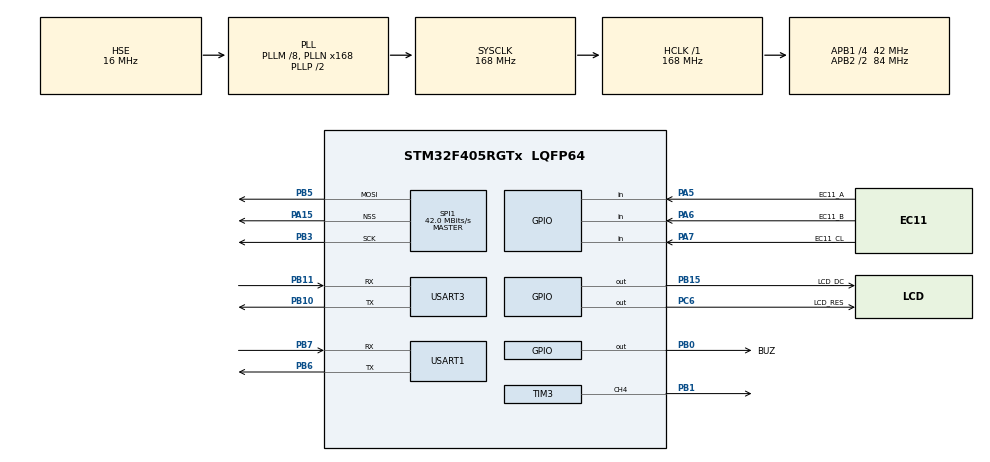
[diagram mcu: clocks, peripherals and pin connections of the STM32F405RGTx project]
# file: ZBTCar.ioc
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Dma.Request0=SPI1_TX
Dma.Request1=USART1_TX
Dma.Request2=USART3_TX
Dma.SPI1_TX.0.Direction=DMA_MEMORY_TO_PERIPH
Dma.SPI1_TX.0.FIFOMode=DMA_FIFOMODE_DISABLE
Dma.SPI1_TX.0.Instance=DMA2_Stream3
Dma.SPI1_TX.0.MemDataAlignment=DMA_MDATAALIGN_BYTE
Dma.SPI1_TX.0.MemInc=DMA_MINC_ENABLE
Dma.SPI1_TX.0.Mode=DMA_NORMAL
Dma.SPI1_TX.0.PeriphDataAlignment=DMA_PDATAALIGN_BYTE
Dma.SPI1_TX.0.PeriphInc=DMA_PINC_DISABLE
Dma.SPI1_TX.0.Priority=DMA_PRIORITY_LOW
Dma.USART1_TX.1.Direction=DMA_MEMORY_TO_PERIPH
Dma.USART1_TX.1.FIFOMode=DMA_FIFOMODE_DISABLE
Dma.USART1_TX.1.Instance=DMA2_Stream7
Dma.USART1_TX.1.MemDataAlignment=DMA_MDATAALIGN_BYTE
Dma.USART1_TX.1.MemInc=DMA_MINC_ENABLE
Dma.USART1_TX.1.Mode=DMA_NORMAL
Dma.USART1_TX.1.PeriphDataAlignment=DMA_PDATAALIGN_BYTE
Dma.USART1_TX.1.PeriphInc=DMA_PINC_DISABLE
Dma.USART1_TX.1.Priority=DMA_PRIORITY_LOW
Dma.USART3_TX.2.Direction=DMA_MEMORY_TO_PERIPH
Dma.USART3_TX.2.FIFOMode=DMA_FIFOMODE_DISABLE
Dma.USART3_TX.2.Instance=DMA1_Stream3
Dma.USART3_TX.2.MemDataAlignment=DMA_MDATAALIGN_BYTE
Dma.USART3_TX.2.MemInc=DMA_MINC_ENABLE
Dma.USART3_TX.2.Mode=DMA_NORMAL
Dma.USART3_TX.2.PeriphDataAlignment=DMA_PDATAALIGN_BYTE
Dma.USART3_TX.2.PeriphInc=DMA_PINC_DISABLE
Dma.USART3_TX.2.Priority=DMA_PRIORITY_LOW
FREERTOS.Tasks01=defaultTask,24,128,StartDefaultTask,Default,NULL,Dynamic,NULL,NULL
Mcu.Family=STM32F4
Mcu.Name=STM32F405RGTx
Mcu.Package=LQFP64
Mcu.UserConstants=LCD_SPI,hspi1;PWM_TIM,htim3;PWM_CH,TIM_CHANNEL_4;PC_UART,huart1;VESC_UART,huart3
NVIC.DMA1_Stream3_IRQn=true\:5\:0\:false\:false\:true\:true\:false\:true
NVIC.DMA2_Stream3_IRQn=true\:5\:0\:false\:false\:true\:true\:false\:true
NVIC.DMA2_Stream7_IRQn=true\:5\:0\:false\:false\:true\:true\:false\:true
NVIC.PriorityGroup=NVIC_PRIORITYGROUP_4
NVIC.TIM8_TRG_COM_TIM14_IRQn=true\:0\:0\:false\:false\:true\:false\:false\:true
NVIC.TimeBase=TIM8_TRG_COM_TIM14_IRQn
NVIC.TimeBaseIP=TIM14
NVIC.USART1_IRQn=true\:5\:0\:false\:false\:true\:true\:true\:true
NVIC.USART3_IRQn=true\:5\:0\:false\:false\:true\:true\:true\:true
PA13.Mode=Serial_Wire
PA13.Signal=SYS_JTMS-SWDIO
PA14.Mode=Serial_Wire
PA14.Signal=SYS_JTCK-SWCLK
PA15.Mode=NSS_Signal_Hard_Output
PA15.Signal=SPI1_NSS
PA5.GPIO_Label=EC11_A
PA5.Signal=GPIO_Input
PA6.GPIO_Label=EC11_B
PA6.Signal=GPIO_Input
PA7.GPIO_Label=EC11_CL
PA7.Signal=GPIO_Input
PB0.GPIO_Label=BUZ
PB0.Signal=GPIO_Output
PB1.Signal=S_TIM3_CH4
PB10.Mode=Asynchronous
PB10.Signal=USART3_TX
PB11.Mode=Asynchronous
PB11.Signal=USART3_RX
PB15.GPIO_Label=LCD_DC
PB15.GPIO_Speed=GPIO_SPEED_FREQ_VERY_HIGH
PB15.PinState=GPIO_PIN_SET
PB15.Signal=GPIO_Output
PB3.Mode=TX_Only_Simplex_Unidirect_Master
PB3.Signal=SPI1_SCK
PB5.Mode=TX_Only_Simplex_Unidirect_Master
PB5.Signal=SPI1_MOSI
PB6.Mode=Asynchronous
PB6.Signal=USART1_TX
PB7.Mode=Asynchronous
PB7.Signal=USART1_RX
PC6.GPIO_Label=LCD_RES
PC6.GPIO_Speed=GPIO_SPEED_FREQ_VERY_HIGH
PC6.PinState=GPIO_PIN_SET
PC6.Signal=GPIO_Output
PH0-OSC_IN.Mode=HSE-External-Oscillator
PH0-OSC_IN.Signal=RCC_OSC_IN
PH1-OSC_OUT.Mode=HSE-External-Oscillator
PH1-OSC_OUT.Signal=RCC_OSC_OUT
ProjectManager.HeapSize=0x800
ProjectManager.StackSize=0x800
ProjectManager.TargetToolchain=EWARM V8.32
RCC.48MHZClocksFreq_Value=84000000
RCC.AHBFreq_Value=168000000
RCC.APB1CLKDivider=RCC_HCLK_DIV4
RCC.APB1Freq_Value=42000000
RCC.APB1TimFreq_Value=84000000
RCC.APB2CLKDivider=RCC_HCLK_DIV2
RCC.APB2Freq_Value=84000000
RCC.APB2TimFreq_Value=168000000
RCC.CortexFreq_Value=168000000
RCC.HCLKFreq_Value=168000000
RCC.HSE_VALUE=16000000
RCC.HSI_VALUE=16000000
RCC.LSE_VALUE=32768
RCC.PLLM=8
RCC.PLLN=168
RCC.PLLSourceVirtual=RCC_PLLSOURCE_HSE
RCC.SYSCLKFreq_VALUE=168000000
RCC.SYSCLKSource=RCC_SYSCLKSOURCE_PLLCLK
RCC.VCOOutputFreq_Value=336000000
SH.S_TIM3_CH4.0=TIM3_CH4,PWM Generation4 CH4
SPI1.CalculateBaudRate=42.0 MBits/s
SPI1.Direction=SPI_DIRECTION_2LINES
SPI1.Mode=SPI_MODE_MASTER
SPI1.VirtualNSS=VM_NSSHARD
SPI1.VirtualType=VM_MASTER
TIM3.Channel-PWM\ Generation4\ CH4=TIM_CHANNEL_4
TIM3.Period=9999
TIM3.Prescaler=167
USART1.VirtualMode=VM_ASYNC
USART3.VirtualMode=VM_ASYNC
VP_FREERTOS_VS_CMSIS_V2.Mode=CMSIS_V2
VP_SYS_VS_tim14.Mode=TIM14
board=custom

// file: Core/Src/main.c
/* USER CODE BEGIN Header */
/**
  ******************************************************************************
  * @file           : main.c
  * @brief          : Main program body
  ******************************************************************************
  * @attention
  *
  * <h2><center>&copy; Copyright (c) 2021 STMicroelectronics.
  * All rights reserved.</center></h2>
  *
  * This software component is licensed by ST under Ultimate Liberty license
  * SLA0044, the "License"; You may not use this file except in compliance with
  * the License. You may obtain a copy of the License at:
  *                             www.st.com/SLA0044
  *
  ******************************************************************************
  */
/* USER CODE END Header */
#include "main.h"
#include "cmsis_os.h"
#include "dma.h"
#include "spi.h"
#include "tim.h"
#include "usart.h"
#include "gpio.h"

/* USER CODE BEGIN Includes */
#include "lcd_lvgl.h"
/* USER CODE END Includes */

void SystemClock_Config(void);
void MX_FREERTOS_Init(void);

int main(void)
{

  /* MCU Configuration--------------------------------------------------------*/

  /* Reset of all peripherals, Initializes the Flash interface and the Systick. */
  HAL_Init();

  /* Configure the system clock */
  SystemClock_Config();

  /* Initialize all configured peripherals */
  MX_GPIO_Init();
  MX_DMA_Init();
  MX_SPI1_Init();
  MX_USART1_UART_Init();
  MX_TIM3_Init();
  MX_USART3_UART_Init();

  /* Init scheduler */
  osKernelInitialize();  /* Call init function for freertos objects (in freertos.c) */
  MX_FREERTOS_Init();
  /* Start scheduler */
  osKernelStart();

  /* We should never get here as control is now taken by the scheduler */
  /* Infinite loop */
  while (1)
  {

  }
}

void SystemClock_Config(void)
{
  RCC_OscInitTypeDef RCC_OscInitStruct = {0};
  RCC_ClkInitTypeDef RCC_ClkInitStruct = {0};

  /** Configure the main internal regulator output voltage
  */
  __HAL_RCC_PWR_CLK_ENABLE();
  __HAL_PWR_VOLTAGESCALING_CONFIG(PWR_REGULATOR_VOLTAGE_SCALE1);
  /** Initializes the RCC Oscillators according to the specified parameters
  * in the RCC_OscInitTypeDef structure.
  */
  RCC_OscInitStruct.OscillatorType = RCC_OSCILLATORTYPE_HSE;
  RCC_OscInitStruct.HSEState = RCC_HSE_ON;
  RCC_OscInitStruct.PLL.PLLState = RCC_PLL_ON;
  RCC_OscInitStruct.PLL.PLLSource = RCC_PLLSOURCE_HSE;
  RCC_OscInitStruct.PLL.PLLM = 8;
  RCC_OscInitStruct.PLL.PLLN = 168;
  RCC_OscInitStruct.PLL.PLLP = RCC_PLLP_DIV2;
  RCC_OscInitStruct.PLL.PLLQ = 4;
  if (HAL_RCC_OscConfig(&RCC_OscInitStruct) != HAL_OK)
  {
    Error_Handler();
  }
  /** Initializes the CPU, AHB and APB buses clocks
  */
  RCC_ClkInitStruct.ClockType = RCC_CLOCKTYPE_HCLK|RCC_CLOCKTYPE_SYSCLK
                              |RCC_CLOCKTYPE_PCLK1|RCC_CLOCKTYPE_PCLK2;
  RCC_ClkInitStruct.SYSCLKSource = RCC_SYSCLKSOURCE_PLLCLK;
  RCC_ClkInitStruct.AHBCLKDivider = RCC_SYSCLK_DIV1;
  RCC_ClkInitStruct.APB1CLKDivider = RCC_HCLK_DIV4;
  RCC_ClkInitStruct.APB2CLKDivider = RCC_HCLK_DIV2;

  if (HAL_RCC_ClockConfig(&RCC_ClkInitStruct, FLASH_LATENCY_5) != HAL_OK)
  {
    Error_Handler();
  }
}

 /**
  * @brief  Period elapsed callback in non blocking mode
  * @note   This function is called  when TIM14 interrupt took place, inside
  * HAL_TIM_IRQHandler(). It makes a direct call to HAL_IncTick() to increment
  * a global variable "uwTick" used as application time base.
  * @param  htim : TIM handle
  * @retval None
  */
void HAL_TIM_PeriodElapsedCallback(TIM_HandleTypeDef *htim)
{
  if (htim->Instance == TIM14) {
    HAL_IncTick();
  }
}

void Error_Handler(void)
{
  __disable_irq();
  while (1)
  {
  }
}

/************************ (C) COPYRIGHT STMicroelectronics *****END OF FILE****/

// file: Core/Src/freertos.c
/* USER CODE BEGIN Header */
/**
  ******************************************************************************
  * File Name          : freertos.c
  * Description        : Code for freertos applications
  ******************************************************************************
  * @attention
  *
  * <h2><center>&copy; Copyright (c) 2021 STMicroelectronics.
  * All rights reserved.</center></h2>
  *
  * This software component is licensed by ST under Ultimate Liberty license
  * SLA0044, the "License"; You may not use this file except in compliance with
  * the License. You may obtain a copy of the License at:
  *                             www.st.com/SLA0044
  *
  ******************************************************************************
  */
/* USER CODE END Header */

#include "FreeRTOS.h"
#include "task.h"
#include "main.h"
#include "cmsis_os.h"

/* USER CODE BEGIN Includes */
#include "lcd_gui.h"
#include "func_drv.h"
#include "func_uart.h"
/* USER CODE END Includes */

/* Definitions for defaultTask */
osThreadId_t defaultTaskHandle;
const osThreadAttr_t defaultTask_attributes = {
  .name = "defaultTask",
  .priority = (osPriority_t) osPriorityNormal,
  .stack_size = 128 * 4
};

void StartDefaultTask(void *argument);

void MX_FREERTOS_Init(void); /* (MISRA C 2004 rule 8.1) */

void MX_FREERTOS_Init(void) {

  /* USER CODE BEGIN RTOS_QUEUES */
  /* add queues, ... */
  buz_queue = xQueueCreate(5,sizeof(uint8_t));
  guival_queue = xQueueCreate(5,sizeof(guival_queue_t));
  /* USER CODE END RTOS_QUEUES */

  /* Create the thread(s) */
  /* creation of defaultTask */
  defaultTaskHandle = osThreadNew(StartDefaultTask, NULL, &defaultTask_attributes);

  /* USER CODE BEGIN RTOS_THREADS */
  /* add threads, ... */
  xTaskCreate(gui_TaskFunction,"Gui_Task",1024,NULL,osPriorityLow,NULL);
  xTaskCreate(drv_TaskFunction,"Drv_Task",32,NULL,osPriorityBelowNormal,NULL);
  xTaskCreate(test_TaskFunction,"Test_Task",32,NULL,osPriorityNormal,NULL);
  /* USER CODE END RTOS_THREADS */

}

void StartDefaultTask(void *argument)
{
  /* USER CODE BEGIN StartDefaultTask */
  /* Infinite loop */
  for(;;)
  {
    lv_tick_inc(5);      //Ϊlvgl�ṩʱ��̶�
    osDelay(5);
  }
  /* USER CODE END StartDefaultTask */
}

/************************ (C) COPYRIGHT STMicroelectronics *****END OF FILE****/
